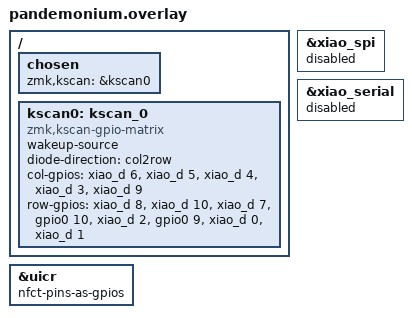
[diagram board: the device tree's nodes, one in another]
/*
 * Copyright (c) 2020 The ZMK Contributors
 *
 * SPDX-License-Identifier: MIT
 */

#include "pandemonium-transforms.dtsi"

/ {
    chosen {
        zmk,kscan = &kscan0;
        /delete-property/ zephyr,console;
        /delete-property/ zephyr,shell-uart;
    };

    kscan0: kscan_0 {
        compatible = "zmk,kscan-gpio-matrix";
        wakeup-source;
        diode-direction = "col2row";

        col-gpios
            = <&xiao_d 6 GPIO_ACTIVE_HIGH>
            , <&xiao_d 5 GPIO_ACTIVE_HIGH>
            , <&xiao_d 4 GPIO_ACTIVE_HIGH>
            , <&xiao_d 3 GPIO_ACTIVE_HIGH>
            , <&xiao_d 9 GPIO_ACTIVE_HIGH>
            ;

        row-gpios
            = <&xiao_d 8  (GPIO_ACTIVE_HIGH | GPIO_PULL_DOWN)>
            , <&xiao_d 10 (GPIO_ACTIVE_HIGH | GPIO_PULL_DOWN)>
            , <&xiao_d 7  (GPIO_ACTIVE_HIGH | GPIO_PULL_DOWN)>
            , <&gpio0 10  (GPIO_ACTIVE_HIGH | GPIO_PULL_DOWN)>
            , <&xiao_d 2  (GPIO_ACTIVE_HIGH | GPIO_PULL_DOWN)>
            , <&gpio0 9   (GPIO_ACTIVE_HIGH | GPIO_PULL_DOWN)>
            , <&xiao_d 0  (GPIO_ACTIVE_HIGH | GPIO_PULL_DOWN)>
            , <&xiao_d 1  (GPIO_ACTIVE_HIGH | GPIO_PULL_DOWN)>
            ;
    };

};

&uicr { nfct-pins-as-gpios; };
&xiao_spi { status = "disabled"; };
&xiao_serial { status = "disabled"; };
